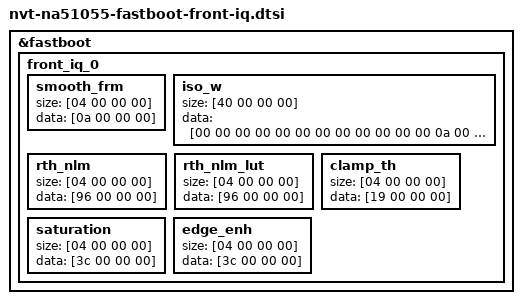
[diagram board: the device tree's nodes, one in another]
/*
 * Novatek Ltd. NA51055 BSP part of dts
 *
 * Cortex-A9
 *
 */

&fastboot {
    front_iq_0 {
        smooth_frm {
			      size = [04 00 00 00];
			      data = [0a 00 00 00];
		        };
        iso_w {
			      size = [40 00 00 00];
			      data = [00 00 00 00 00 00 00 00 00 00 00 00 0a 00 00 00 14 00 00 00 28 00 00 00 50 00 00 00 64 00 00 00 64 00 00 00 64 00 00 00 64 00 00 00 64 00 00 00 64 00 00 00 64 00 00 00 64 00 00 00 64 00 00 00];
		        };
        rth_nlm {
			      size = [04 00 00 00];
			      data = [96 00 00 00];
		        };
        rth_nlm_lut {
			      size = [04 00 00 00];
			      data = [96 00 00 00];
		        };
        clamp_th {
			      size = [04 00 00 00];
			      data = [19 00 00 00];
		        };
        saturation {
			      size = [04 00 00 00];
			      data = [3c 00 00 00];
		        };
        edge_enh {
			      size = [04 00 00 00];
			      data = [3c 00 00 00];
		        };
		};
};
